VERSION "MUR_Telemetry_CAN_v1.1"

NS_ :

BS_:

BU_: DASH PDU SBG TELEMETRY ECU

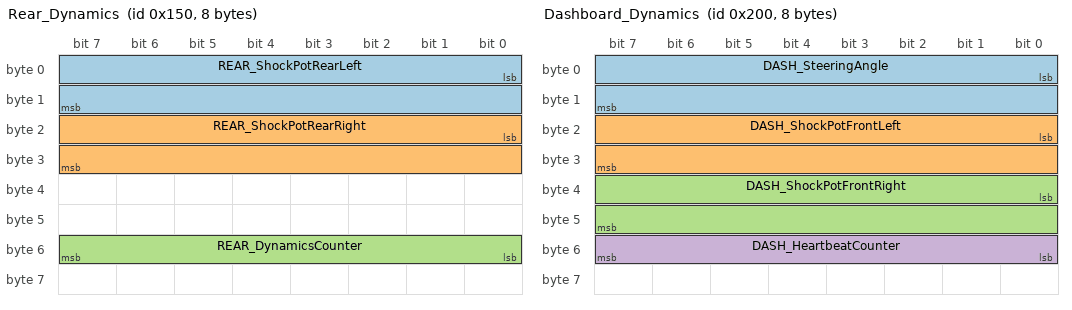
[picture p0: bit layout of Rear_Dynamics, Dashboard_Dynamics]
BO_ 336 Rear_Dynamics: 8 ECU
 SG_ REAR_ShockPotRearLeft : 0|16@1+ (0.1,0) [0|500] "mm" TELEMETRY
 SG_ REAR_ShockPotRearRight : 16|16@1+ (0.1,0) [0|500] "mm" TELEMETRY
 SG_ REAR_DynamicsCounter : 48|8@1+ (1,0) [0|255] "" TELEMETRY

BO_ 512 Dashboard_Dynamics: 8 DASH
 SG_ DASH_SteeringAngle : 0|16@1- (0.1,0) [-1800|1800] "deg" TELEMETRY
 SG_ DASH_ShockPotFrontLeft : 16|16@1+ (0.1,0) [0|500] "mm" TELEMETRY
 SG_ DASH_ShockPotFrontRight : 32|16@1+ (0.1,0) [0|500] "mm" TELEMETRY
 SG_ DASH_HeartbeatCounter : 48|8@1+ (1,0) [0|255] "" TELEMETRY

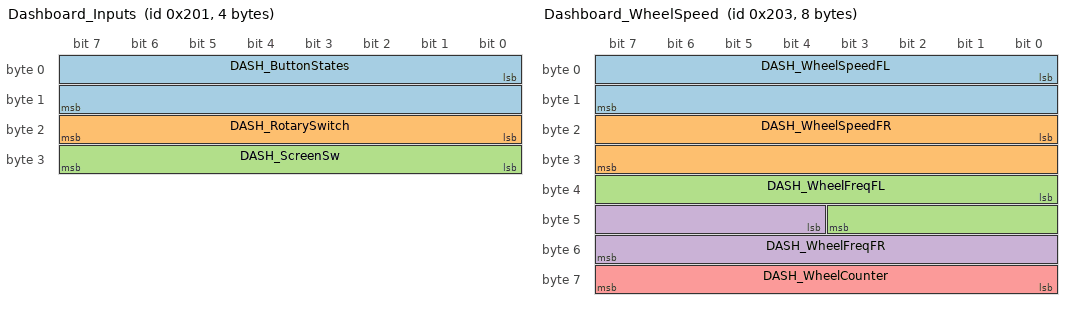
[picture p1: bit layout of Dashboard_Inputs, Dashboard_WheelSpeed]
BO_ 513 Dashboard_Inputs: 4 DASH
 SG_ DASH_ButtonStates : 0|16@1+ (1,0) [0|65535] "" TELEMETRY
 SG_ DASH_RotarySwitch : 16|8@1+ (1,0) [0|15] "" TELEMETRY
 SG_ DASH_ScreenSw : 24|8@1+ (1,0) [0|255] "" TELEMETRY,ECU

BO_ 514 Dashboard_Environment: 4 DASH
 SG_ DASH_WindSpeed : 0|16@1+ (0.1,0) [0|6553.5] "m/s" TELEMETRY

BO_ 515 Dashboard_WheelSpeed: 8 DASH
 SG_ DASH_WheelSpeedFL : 0|16@1+ (0.1,0) [0|6553.4] "rpm" TELEMETRY
 SG_ DASH_WheelSpeedFR : 16|16@1+ (0.1,0) [0|6553.4] "rpm" TELEMETRY
 SG_ DASH_WheelFreqFL : 32|12@1+ (1,0) [0|4095] "Hz" TELEMETRY
 SG_ DASH_WheelFreqFR : 44|12@1+ (1,0) [0|4095] "Hz" TELEMETRY
 SG_ DASH_WheelCounter : 56|8@1+ (1,0) [0|255] "" TELEMETRY

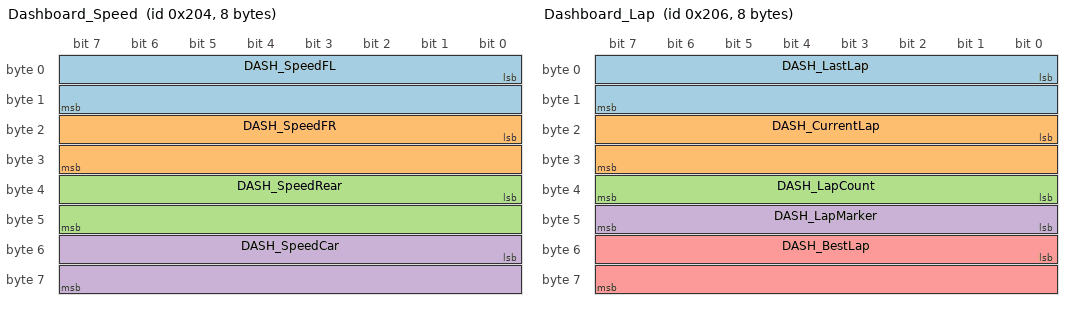
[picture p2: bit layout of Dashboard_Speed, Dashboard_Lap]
BO_ 516 Dashboard_Speed: 8 DASH
 SG_ DASH_SpeedFL : 0|16@1+ (0.1,0) [0|6553.4] "km/h" TELEMETRY
 SG_ DASH_SpeedFR : 16|16@1+ (0.1,0) [0|6553.4] "km/h" TELEMETRY
 SG_ DASH_SpeedRear : 32|16@1+ (0.1,0) [0|6553.4] "km/h" TELEMETRY
 SG_ DASH_SpeedCar : 48|16@1+ (0.1,0) [0|6553.4] "km/h" TELEMETRY

BO_ 518 Dashboard_Lap: 8 DASH
 SG_ DASH_LastLap : 0|16@1+ (0.01,0) [0|655.34] "s" TELEMETRY
 SG_ DASH_CurrentLap : 16|16@1+ (0.01,0) [0|655.34] "s" TELEMETRY
 SG_ DASH_LapCount : 32|8@1+ (1,0) [0|255] "" TELEMETRY
 SG_ DASH_LapMarker : 40|8@1+ (1,0) [0|1] "" TELEMETRY
 SG_ DASH_BestLap : 48|16@1+ (0.01,0) [0|655.34] "s" TELEMETRY

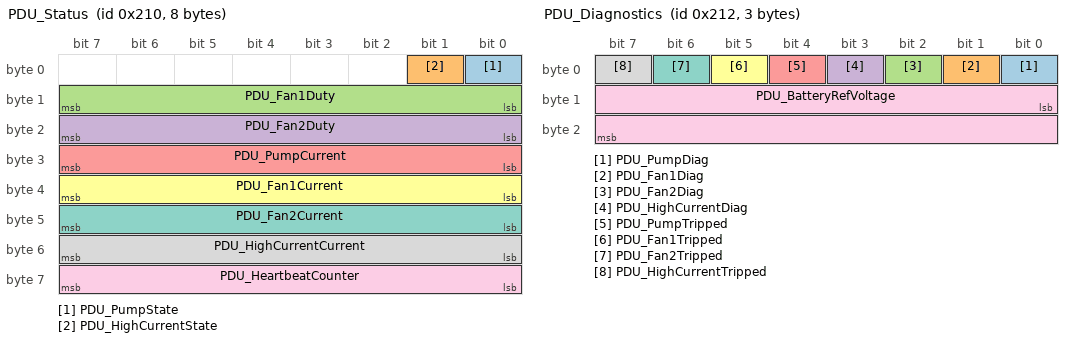
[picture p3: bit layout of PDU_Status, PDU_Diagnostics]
BO_ 528 PDU_Status: 8 PDU
 SG_ PDU_PumpState : 0|1@1+ (1,0) [0|1] "" TELEMETRY,ECU
 SG_ PDU_HighCurrentState : 1|1@1+ (1,0) [0|1] "" TELEMETRY,ECU
 SG_ PDU_Fan1Duty : 8|8@1+ (1,0) [0|100] "%" TELEMETRY,ECU
 SG_ PDU_Fan2Duty : 16|8@1+ (1,0) [0|100] "%" TELEMETRY,ECU
 SG_ PDU_PumpCurrent : 24|8@1+ (0.1,0) [0|25.5] "A" TELEMETRY,ECU
 SG_ PDU_Fan1Current : 32|8@1+ (0.1,0) [0|25.5] "A" TELEMETRY,ECU
 SG_ PDU_Fan2Current : 40|8@1+ (0.1,0) [0|25.5] "A" TELEMETRY,ECU
 SG_ PDU_HighCurrentCurrent : 48|8@1+ (0.1,0) [0|25.5] "A" TELEMETRY,ECU
 SG_ PDU_HeartbeatCounter : 56|8@1+ (1,0) [0|255] "" TELEMETRY

BO_ 530 PDU_Diagnostics: 3 PDU
 SG_ PDU_PumpDiag : 0|1@1+ (1,0) [0|1] "" TELEMETRY,ECU
 SG_ PDU_Fan1Diag : 1|1@1+ (1,0) [0|1] "" TELEMETRY,ECU
 SG_ PDU_Fan2Diag : 2|1@1+ (1,0) [0|1] "" TELEMETRY,ECU
 SG_ PDU_HighCurrentDiag : 3|1@1+ (1,0) [0|1] "" TELEMETRY,ECU
 SG_ PDU_PumpTripped : 4|1@1+ (1,0) [0|1] "" TELEMETRY,ECU
 SG_ PDU_Fan1Tripped : 5|1@1+ (1,0) [0|1] "" TELEMETRY,ECU
 SG_ PDU_Fan2Tripped : 6|1@1+ (1,0) [0|1] "" TELEMETRY,ECU
 SG_ PDU_HighCurrentTripped : 7|1@1+ (1,0) [0|1] "" TELEMETRY,ECU
 SG_ PDU_BatteryRefVoltage : 8|16@1+ (0.01,0) [0|655.35] "V" TELEMETRY,ECU

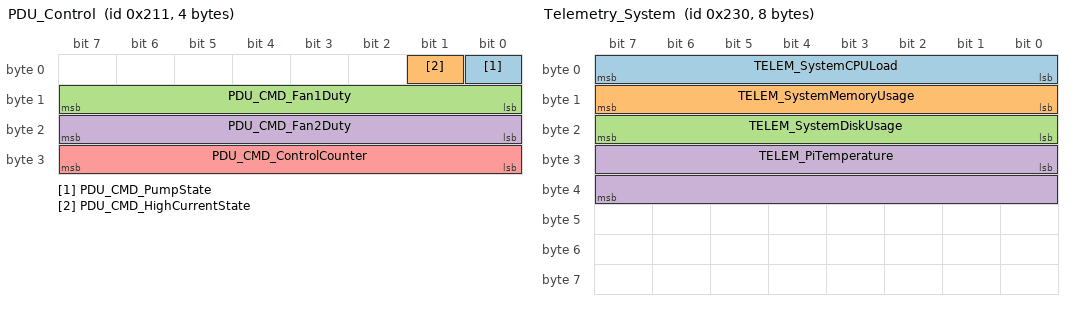
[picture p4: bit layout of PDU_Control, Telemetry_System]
BO_ 529 PDU_Control: 4 ECU
 SG_ PDU_CMD_PumpState : 0|1@1+ (1,0) [0|1] "" PDU,TELEMETRY
 SG_ PDU_CMD_HighCurrentState : 1|1@1+ (1,0) [0|1] "" PDU,TELEMETRY
 SG_ PDU_CMD_Fan1Duty : 8|8@1+ (1,0) [0|100] "%" PDU,TELEMETRY
 SG_ PDU_CMD_Fan2Duty : 16|8@1+ (1,0) [0|100] "%" PDU,TELEMETRY
 SG_ PDU_CMD_ControlCounter : 24|8@1+ (1,0) [0|255] "" PDU,TELEMETRY

BO_ 560 Telemetry_System: 8 TELEMETRY
 SG_ TELEM_SystemCPULoad : 0|8@1+ (1,0) [0|100] "%" DASH
 SG_ TELEM_SystemMemoryUsage : 8|8@1+ (1,0) [0|100] "%" DASH
 SG_ TELEM_SystemDiskUsage : 16|8@1+ (1,0) [0|100] "%" DASH
 SG_ TELEM_PiTemperature : 24|16@1- (0.1,0) [-3276.8|3276.7] "degC" DASH

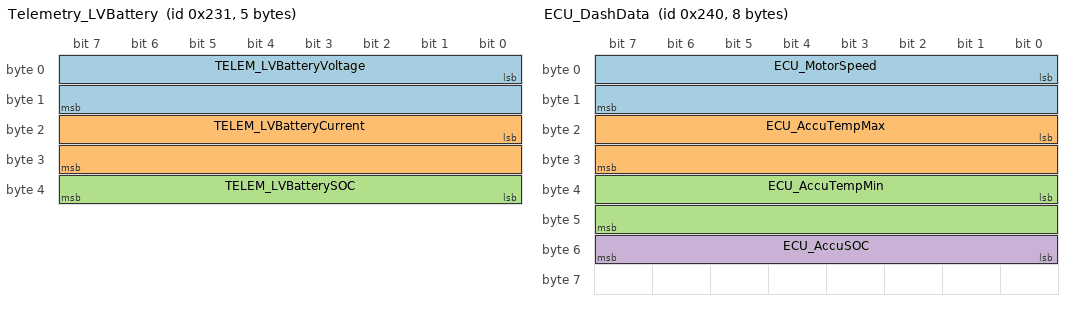
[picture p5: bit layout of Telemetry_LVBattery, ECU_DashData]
BO_ 561 Telemetry_LVBattery: 5 TELEMETRY
 SG_ TELEM_LVBatteryVoltage : 0|16@1+ (0.01,0) [0|655.35] "V" DASH,ECU
 SG_ TELEM_LVBatteryCurrent : 16|16@1- (0.1,0) [-3276.8|3276.7] "A" DASH,ECU
 SG_ TELEM_LVBatterySOC : 32|8@1+ (1,0) [0|100] "%" DASH,ECU

BO_ 576 ECU_DashData: 8 ECU
 SG_ ECU_MotorSpeed : 0|16@1+ (1,0) [0|10000] "rpm" DASH,TELEMETRY
 SG_ ECU_AccuTempMax : 16|16@1- (0.1,0) [-3276.8|3276.7] "degC" DASH,TELEMETRY
 SG_ ECU_AccuTempMin : 32|16@1- (0.1,0) [-3276.8|3276.7] "degC" DASH,TELEMETRY
 SG_ ECU_AccuSOC : 48|8@1+ (1,0) [0|100] "%" DASH,TELEMETRY

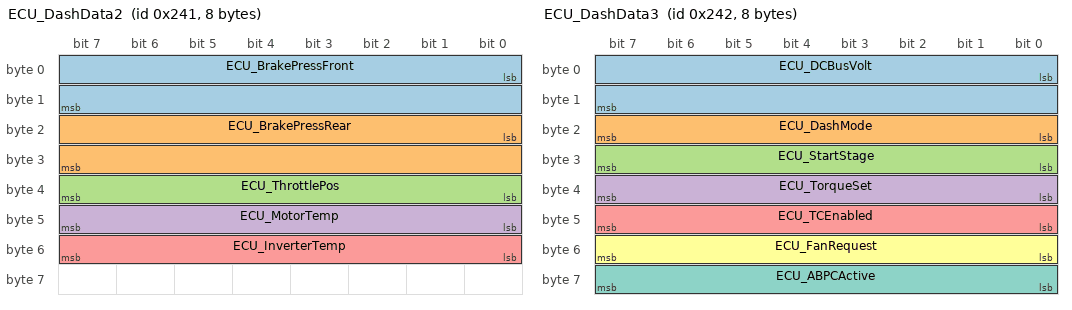
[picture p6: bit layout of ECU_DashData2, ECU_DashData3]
BO_ 577 ECU_DashData2: 8 ECU
 SG_ ECU_BrakePressFront : 0|16@1+ (0.1,0) [0|2000] "psi" DASH,TELEMETRY
 SG_ ECU_BrakePressRear : 16|16@1+ (0.1,0) [0|2000] "psi" DASH,TELEMETRY
 SG_ ECU_ThrottlePos : 32|8@1+ (1,0) [0|100] "%" DASH,TELEMETRY
 SG_ ECU_MotorTemp : 40|8@1+ (1,-40) [-40|214] "degC" DASH,TELEMETRY
 SG_ ECU_InverterTemp : 48|8@1+ (1,-40) [-40|214] "degC" DASH,TELEMETRY

BO_ 578 ECU_DashData3: 8 ECU
 SG_ ECU_DCBusVolt : 0|16@1+ (0.1,0) [0|500] "V" DASH,TELEMETRY
 SG_ ECU_DashMode : 16|8@1+ (1,0) [0|5] "" DASH,TELEMETRY
 SG_ ECU_StartStage : 24|8@1+ (1,0) [0|4] "" DASH,TELEMETRY
 SG_ ECU_TorqueSet : 32|8@1+ (1,0) [0|254] "Nm" DASH,TELEMETRY
 SG_ ECU_TCEnabled : 40|8@1+ (1,0) [0|1] "" DASH,TELEMETRY
 SG_ ECU_FanRequest : 48|8@1+ (1,0) [0|1] "" DASH,TELEMETRY
 SG_ ECU_ABPCActive : 56|8@1+ (1,0) [0|1] "" DASH,TELEMETRY

BO_ 579 ECU_DashSOC: 2 ECU
 SG_ ECU_AccuSOCMin : 0|16@1+ (0.1,0) [0|100] "%" DASH,TELEMETRY

BO_ 128 MUR_Fault: 8 Vector__XXX
 SG_ FAULT_Node M : 0|8@1+ (1,0) [0|255] "" TELEMETRY
 SG_ FAULT_Bitmask_Pedalbox m1 : 8|32@1+ (1,0) [0|4294967295] "" TELEMETRY
 SG_ FAULT_Bitmask_Dash m2 : 8|32@1+ (1,0) [0|4294967295] "" TELEMETRY
 SG_ FAULT_Bitmask_Rear m3 : 8|32@1+ (1,0) [0|4294967295] "" TELEMETRY
 SG_ FAULT_Bitmask_TTCS m4 : 8|32@1+ (1,0) [0|4294967295] "" TELEMETRY
 SG_ FAULT_Bitmask_Charger m5 : 8|32@1+ (1,0) [0|4294967295] "" TELEMETRY
 SG_ FAULT_Counter : 56|8@1+ (1,0) [0|255] "" TELEMETRY

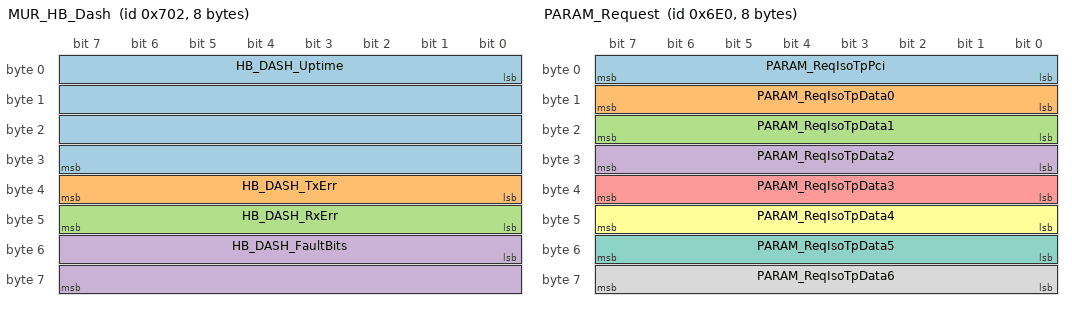
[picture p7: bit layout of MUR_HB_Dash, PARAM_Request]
BO_ 1794 MUR_HB_Dash: 8 DASH
 SG_ HB_DASH_Uptime : 0|32@1+ (1,0) [0|4294967295] "s" TELEMETRY
 SG_ HB_DASH_TxErr : 32|8@1+ (1,0) [0|255] "" TELEMETRY
 SG_ HB_DASH_RxErr : 40|8@1+ (1,0) [0|255] "" TELEMETRY
 SG_ HB_DASH_FaultBits : 48|16@1+ (1,0) [0|65535] "" TELEMETRY

BO_ 1760 PARAM_Request: 8 Vector__XXX
 SG_ PARAM_ReqIsoTpPci : 0|8@1+ (1,0) [0|255] "" Vector__XXX
 SG_ PARAM_ReqIsoTpData0 : 8|8@1+ (1,0) [0|255] "" Vector__XXX
 SG_ PARAM_ReqIsoTpData1 : 16|8@1+ (1,0) [0|255] "" Vector__XXX
 SG_ PARAM_ReqIsoTpData2 : 24|8@1+ (1,0) [0|255] "" Vector__XXX
 SG_ PARAM_ReqIsoTpData3 : 32|8@1+ (1,0) [0|255] "" Vector__XXX
 SG_ PARAM_ReqIsoTpData4 : 40|8@1+ (1,0) [0|255] "" Vector__XXX
 SG_ PARAM_ReqIsoTpData5 : 48|8@1+ (1,0) [0|255] "" Vector__XXX
 SG_ PARAM_ReqIsoTpData6 : 56|8@1+ (1,0) [0|255] "" Vector__XXX

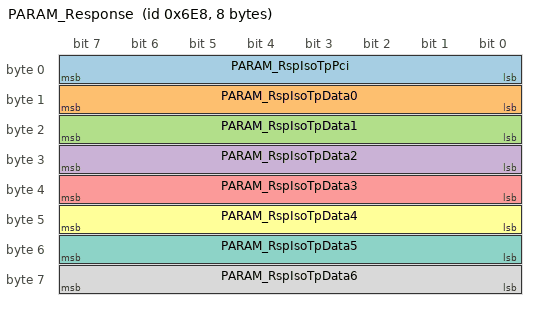
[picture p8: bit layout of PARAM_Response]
BO_ 1768 PARAM_Response: 8 Vector__XXX
 SG_ PARAM_RspIsoTpPci : 0|8@1+ (1,0) [0|255] "" Vector__XXX
 SG_ PARAM_RspIsoTpData0 : 8|8@1+ (1,0) [0|255] "" Vector__XXX
 SG_ PARAM_RspIsoTpData1 : 16|8@1+ (1,0) [0|255] "" Vector__XXX
 SG_ PARAM_RspIsoTpData2 : 24|8@1+ (1,0) [0|255] "" Vector__XXX
 SG_ PARAM_RspIsoTpData3 : 32|8@1+ (1,0) [0|255] "" Vector__XXX
 SG_ PARAM_RspIsoTpData4 : 40|8@1+ (1,0) [0|255] "" Vector__XXX
 SG_ PARAM_RspIsoTpData5 : 48|8@1+ (1,0) [0|255] "" Vector__XXX
 SG_ PARAM_RspIsoTpData6 : 56|8@1+ (1,0) [0|255] "" Vector__XXX

CM_ BU_ DASH "Dashboard Sensor Node - steering, shock pots, driver buttons, front wheel speeds, wind speed";
CM_ BU_ PDU "Power Distribution Unit - 4 switched high-side outputs (Pump, Fan1, Fan2, HighCurrent) each with current sense + hardware diagnostic feedback, per the PDM_M26 hardware bring-up. Design brief only defined PDU_Status (receive-only feedback, no command messages); PDU_Control and PDU_Diagnostics are MUR additions (see their CM_ comments).";
CM_ BU_ SBG "2x SBG Ellipse-D GNSS/INS units (front + rear). CAN ID block 0x220-0x22F reserved for SBG traffic: front 0x220-0x227, rear 0x228-0x22F. Frames are defined in vendor/SBG_Ellipse.dbc (derived from SBG's official sbgCan.dbc, IDs remapped in sbgCenter), not here - load that file alongside this one.";
CM_ BU_ TELEMETRY "Telemetry Unit (Raspberry Pi) - silently captures all Telemetry CAN traffic, also broadcasts system health + LV battery data";
CM_ BU_ ECU "Engine/Electronic Control Unit - dual-homed node, also on Control CAN (see control_can DBC). Previously listed as a receiver of PDU_Status and Telemetry_LVBattery without being declared here. HARDWARE NOTE: requires a second CAN transceiver on the ECU - confirm before finalising.";
CM_ BO_ 336 "ECU rear shockpots, 100 Hz on Telemetry CAN. Same wire layout as the legacy Control CAN Rear_Dynamics used by sn_demo. AIN1/PB1 = left, AIN0/PA6 = right. Firmware defaults to pin-mV bench mode until per-corner calibration exists: raw fields contain ADC pin millivolts, so divide DBC-decoded travel by 0.1 to recover mV. 0xFFFF = invalid; calibrated mode uses the declared 0.1 mm/count scale.";
CM_ BO_ 512 "Dashboard steering/suspension + heartbeat. Transmit rate 100 Hz (FAST).";
CM_ SG_ 512 DASH_SteeringAngle "Signed to allow left/right steering deflection.";
CM_ BO_ 513 "Dashboard driver button states + rotary mode switch. Transmit rate 20 Hz.";
CM_ SG_ 513 DASH_ButtonStates "Bit-per-button: bit i = the dashboard's din-gpios[i], debounced, 1 = pressed. Per the team's pinout (2026-11-14): bit 2 = ready-to-drive (DIN[2], PC0), bit 4 = torque down (DIN[4], PA3), bit 5 = torque up (DIN[5], PA4), bit 6 = fans on/off (DIN[6], PA5), bit 7 = drive mode (DIN[7], PA7). Bits 3 and 8 are the wheel-speed encoder DINs, always 0 here. main_compute's MC_DASH_BTN_* constants must match.";
CM_ SG_ 513 DASH_RotarySwitch "Rotary switch position index (0-15). ASSUMPTION - confirm number of switch positions.";
CM_ SG_ 513 DASH_ScreenSw "MUR ADDITION (PROVISIONAL): the screen's CAN switches as last received on Dash CAN (Screen_Switches there), relayed so the ECU can act on them: bits 0-6 = CAN switches 1-7 (bit n-1 = switch n): 1 = torque down, 2 = torque up, 3 = traction control; 4 is unused (it set the GPS lap marker until 2026-11-19; laps are now marked with the RTD button, see Dashboard_Lap). Bit 7 = 1 while the screen is being heard (a Screen_Switches frame within the last 500 ms); while it is 0 the whole byte is 0 and means nothing. The screen's switches are toggles, so a CHANGE of bits 0-6 is one press, in either direction - but only between two samples with bit 7 set: the ECU takes the first sample after the screen (re)appears as its new baseline, since a rebooted screen comes back with its switches reset.";
CM_ BO_ 514 "Dashboard wind speed sensor. Transmit rate 10 Hz (MEDIUM).";
CM_ BO_ 515 "MUR ADDITION (PROVISIONAL): front wheel speeds from the two encoder DINs on the dashboard node (DIN[3] PC13 = FL, DIN[8] PC5 = FR), measured by EXTI edge timing (firmware/lib/dash/dash_wheel). Transmit rate 100 Hz (FAST).";
CM_ SG_ 515 DASH_WheelSpeedFL "Wheel rpm = pulse frequency x 60 / pulses-per-rev. 0xFFFF (6553.5) = invalid: encoder pulses-per-rev not calibrated yet (TODO(calib)) - read DASH_WheelFreqFL instead. 0 after ~0.5 s with no pulse.";
CM_ SG_ 515 DASH_WheelSpeedFR "See DASH_WheelSpeedFL.";
CM_ SG_ 515 DASH_WheelFreqFL "Raw encoder pulse frequency, independent of any calibration - the bench/sanity view. Saturates at 4095 (= at least 4095 Hz).";
CM_ SG_ 515 DASH_WheelFreqFR "See DASH_WheelFreqFL.";
CM_ SG_ 515 DASH_WheelCounter "Increments every frame; a frozen counter means a stalled node.";
CM_ BO_ 528 "MUR ADDITION (PROVISIONAL - pending telemetry team sign-off): supersedes the original 2-bit pump/fan on-off design-brief layout with the real PDM_M26 hardware's 4-channel shape (Pump/Fan1/Fan2/HighCurrent) - this was the 'byte 2 reserved for future PDU_FanSpeed' the original comment anticipated, now split into per-fan duty since there are two independently-driven fans. PDU_Fan1Duty/PDU_Fan2Duty are 0-100% PWM duty (0 = off); Pump/HighCurrent are simple on/off high-side switches with no PWM hardware. Currents are the per-channel sense readings (0.1 A/LSB) used for the firmware's own overcurrent protection, republished here for telemetry. Diagnostic pin state and latched trip flags moved to PDU_Diagnostics (0x212) to keep this message's transmit rate (10 Hz) fast without carrying slow-changing fault bits. Transmit rate unchanged at 10 Hz (SLOW).";
CM_ BO_ 530 "MUR ADDITION (PROVISIONAL - pending telemetry team sign-off): PDU per-channel hardware diagnostic pin state (fault while driven) and latched software overcurrent-trip flags, split out of PDU_Status since these change far less often. Also carries PDU_BatteryRefVoltage (PDM_M26's PA0 sense channel) for LV rail monitoring. Transmit rate 2 Hz (SLOW).";
CM_ BO_ 529 "MUR ADDITION (PROVISIONAL - pending telemetry team sign-off): ECU-to-PDU command, added because PDU_Status (0x210) is receive-only feedback with no corresponding command message defined anywhere in this bus's design brief, yet the ECU/VCU role genuinely needs to drive pump/fan/high-current state (cooling-loop control tied to Car.Data.State and DrivingState in the ported control logic). Extended alongside PDU_Status's 2026 hardware-accurate redesign: PDU_CMD_Fan1Duty/PDU_CMD_Fan2Duty (0-100% PWM) replace the old single fan on/off bit, PDU_CMD_HighCurrentState added. ControlCounter kept at the end of the frame so a frozen command stream is detectable the same way other MUR-added messages already are (see MUR_HB_* / Rear_* counter convention) - PDM firmware fails all four channels to OFF/0% if this counter stops advancing. Transmit rate: on-change plus a slow cyclic backstop, TBD alongside the rest of this file's provisional messages.";
CM_ BO_ 560 "Telemetry Pi system health (CPU/mem/disk/temp), broadcast for dashboard display. Transmit rate 5 Hz.";
CM_ BO_ 561 "Telemetry Pi: the LV battery with the lower state of charge. The Pi reads both Allion AL1220-BT batteries over Bluetooth (bms_telemetry) and sends this frame for whichever fresh battery reports the lower SoC; voltage and current are that same battery's. A battery is fresh if it reported in the last 10 s. With no fresh battery the frame is still sent, with every signal at its invalid value. No frame at all means the Pi or its bridge is down. Transmit rate 2 Hz (SLOW).";
CM_ SG_ 561 TELEM_LVBatteryVoltage "LV battery terminal voltage, from the battery's own BMS. Raw 0xFFFF = invalid (no fresh battery). Battery reports mV: assumed from its readings, not yet checked against a meter.";
CM_ SG_ 561 TELEM_LVBatteryCurrent "LV battery current, from the battery's own BMS; positive = discharging, negative = charging (the battery's own sign). Raw 0x7FFF = invalid (no fresh battery). Battery reports mA: assumed, not yet checked against a clamp meter.";
CM_ SG_ 561 TELEM_LVBatterySOC "State of charge of the lower of the LV batteries, whole percent, rounded down from the battery BMS's 0.01 % value. Raw 0xFF = invalid (no fresh battery). Only as good as the battery's own SoC estimate.";
CM_ BO_ 128 "MUR ADDITION (PROVISIONAL - pending telemetry team sign-off): latched fault broadcast, any MUR sensor node transmits on fault raise (EVENT). FAULT_Node identifies the sender (1=Pedalbox 2=Dashboard 3=Rear 4=TTCS). Same message exists on Control CAN for nodes homed there.";
CM_ SG_ 128 FAULT_Node "Sending node, and the multiplexor: each node's fault mask has its own FAULT_Bitmask_<node> signal, because the bit numbers mean different faults on each node.";
CM_ SG_ 128 FAULT_Bitmask_Pedalbox "The Pedalbox's latched fault mask, sent when FAULT_Node is the Pedalbox. Same bits as PEDAL_BSEStatus and HB_PEDAL_FaultBits (firmware/lib/pedal/include/pedal_faults.h in mur-embedded). Bits 2 to 6 are reserved there and not raised yet.
bit 0: APPS implausible; Accelerator pedal sensors disagree; warning
bit 1: Pedal cal invalid; Pedalbox calibration invalid; warning
bit 2: BSE active; Brake system encoder active; warning
bit 3: BSPD trip; BSPD fault, shutdown circuit opened; shutdown
bit 4: APPS A out of range; Accelerator pedal sensor A outside its plausible range; warning
bit 5: APPS B out of range; Accelerator pedal sensor B outside its plausible range; warning
bit 6: Brake out of range; Brake pressure sensor outside its plausible range; warning";
CM_ SG_ 128 FAULT_Bitmask_Dash "The dashboard's latched fault mask, sent when FAULT_Node is the dashboard. Only bit 0 is used (firmware/apps/dashboard in mur-embedded); the real fault map is still TBD.
bit 0: Analog dead; Dashboard ADC failed to start; warning";
CM_ SG_ 128 FAULT_Bitmask_Rear "The rear node's latched fault mask, sent when FAULT_Node is the rear node. There is no rear node firmware yet; bit 0 is the bench convention firmware/apps/sn_demo in mur-embedded uses.
bit 0: Analog dead; Rear node ADC failed to start; warning";
CM_ SG_ 128 FAULT_Bitmask_TTCS "The car TTCS's full latched fault mask, sent when FAULT_Node is the TTCS (firmware/lib/ttcs/include/ttcs_faults.h in mur-embedded). HB_TTCS_FaultBits carries only the low 16 bits; bits 16 and 17 reach only this signal. Bits 0 to 2 mirror the MSS fault lines live and the MSS itself opens the shutdown circuit for them. The other shutdown bits are TTCS_SDC_TRIP_MASK, still provisional pending safety-team sign-off. The car app never raises the charger bits 18 to 21.
bit 0: IMD trip; IMD fault, shutdown circuit opened; shutdown
bit 1: PDOC trip; PDOC fault, shutdown circuit opened; shutdown
bit 2: BMS trip; BMS fault, shutdown circuit opened; shutdown
bit 3: HV overcurrent; HV overcurrent measured by the TTCS; shutdown
bit 4: ENNOID comms lost; ENNOID BMS status stream stale; shutdown
bit 5: ECU comms lost; ECU_Status stream stale; shutdown
bit 6: AIR implausible; AIR feedback disagrees with the expected state; warning
bit 7: IMD no signal; No PWM edges from the IMD; warning
bit 8: Cell overvoltage; Highest cell voltage over its limit; shutdown
bit 9: Cell undervoltage; Lowest cell voltage under its limit; shutdown
bit 10: Pack overvoltage; Pack voltage over its limit; shutdown
bit 11: Pack undervoltage; Pack voltage under its limit; shutdown
bit 12: Battery overtemp; Battery high temperature over its limit; shutdown
bit 13: Current while blocked; Current flowing while the ENNOID BMS prohibits it; shutdown
bit 14: Current mismatch; TTCS and ENNOID current readings disagree; shutdown
bit 15: Battery data bad; Battery data implausible or calibration not configured; shutdown
bit 16: Cell imbalance; Weak or imbalanced cell, derate and investigate; warning
bit 17: Current over limit; Current far above the computed discharge or charge limit for a sustained window; shutdown";
CM_ SG_ 128 FAULT_Bitmask_Charger "The charge-cart TTCS board's latched fault mask, sent when FAULT_Node is the charger (firmware/apps/charger in mur-embedded, cart bus only). Same bit numbers as the car TTCS; shutdown marks TTCS_CART_SDC_TRIP_MASK, still provisional pending safety-team sign-off. The cart has no ECU, so bit 5 is never raised there.
bit 0: IMD trip; IMD fault, shutdown circuit opened; shutdown
bit 1: PDOC trip; PDOC fault line asserted, not a cart trip; warning
bit 2: BMS trip; BMS fault, shutdown circuit opened; shutdown
bit 3: HV overcurrent; HV overcurrent measured by the TTCS; warning
bit 4: ENNOID comms lost; ENNOID BMS status stream stale; shutdown
bit 6: AIR implausible; AIR feedback disagrees with the expected state; warning
bit 7: IMD no signal; No PWM edges from the IMD; warning
bit 8: Cell overvoltage; Highest cell voltage over its limit; shutdown
bit 9: Cell undervoltage; Lowest cell voltage under its limit; shutdown
bit 10: Pack overvoltage; Pack voltage over its limit; shutdown
bit 11: Pack undervoltage; Pack voltage under its limit; shutdown
bit 12: Battery overtemp; Battery high temperature over its limit; shutdown
bit 13: Current while blocked; Current flowing while the ENNOID BMS prohibits it; shutdown
bit 14: Current mismatch; TTCS and ENNOID current readings disagree; warning
bit 15: Battery data bad; Battery data implausible or calibration not configured; shutdown
bit 16: Cell imbalance; Weak or imbalanced cell, derate and investigate; warning
bit 17: Current over limit; Current far above the computed discharge or charge limit for a sustained window; shutdown
bit 18: Charger comms lost; Charger status stale while charging; shutdown
bit 19: Charger fault; Charger reports its own fault; shutdown
bit 20: Charger voltage mismatch; Charger output voltage disagrees with the ENNOID pack voltage; shutdown
bit 21: Charger overcurrent; Charger output current above its command plus tolerance; shutdown";
CM_ BO_ 576 "MUR ADDITION (PROVISIONAL): driver-display data from the ECU, which sits on both Tractive and Telemetry CAN and can see what the dashboard cannot. Transmit rate 10 Hz (the ECU's best-effort thread). 8 bytes from day one; byte 7 is still reserved: add new display signals there, byte-aligned and 8 or 16 bits wide so the MFD28's DSS import reads them cleanly, and never move, resize or rescale an existing one. The dashboard forwards this frame to Dash CAN byte-for-byte, so it must stay identical in mur_dashboard_can.dbc (scripts/validate.py checks); adding a signal then needs no dashboard firmware change.";
CM_ SG_ 576 ECU_MotorSpeed "Motor speed magnitude in rpm, from the inverter's INV_MotorPosition on Tractive CAN, clipped to 0-10000 by the ECU; no direction. 0xFFFF = invalid: the ECU has not heard the inverter yet, or has lost it (comms timeout).";
CM_ SG_ 576 ECU_AccuTempMax "Canonical car accumulator maximum, converted by ECU using voltage recovery and Table 5. Prefer complete fresh sweeps; if no sweep frames are fresh, use a fresh mapped summary maximum (1 degC input resolution). Partial or invalid live sweeps prevent fallback. 0x7FFF is invalid. Identical ECU_DashData bytes reach TTCS on Control CAN and screen on Telemetry/Dash CAN.";
CM_ SG_ 576 ECU_AccuTempMin "Corrected minimum from complete fresh sensor sweeps. 0x7FFF is invalid, including during summary-maximum fallback; summary supplies no minimum.";
CM_ SG_ 576 ECU_AccuSOC "Accumulator SOC in whole percent. ECU firmware with ECU_DashSOC derives this from TTCS_ModelSOCMin; older firmware uses ENNOID summary SOC. 0xFF = unavailable.";
CM_ BO_ 579 "Driver display SOC at 10 Hz. ECU publishes on Telemetry CAN; dashboard forwards the same bytes to Dash CAN.";
CM_ SG_ 579 ECU_AccuSOCMin "Lowest TTCS model group SOC at 0.1 percent per count. Raw 0xFFFF (6553.5 percent) means TTCS SOC is invalid or stale. Display only.";
CM_ BO_ 516 "MUR ADDITION (PROVISIONAL): wheel speeds in km/h for the driver's screen, computed on the dashboard node (firmware/lib/dash/dash_speed) and sent with identical bytes on Telemetry and Dash CAN (scripts/validate.py FORWARDED keeps the two definitions the same). Transmit rate 20 Hz. Same equations as mur-embedded's tools/bench/mur_can.py: 0.0766 km/h per wheel rpm (a 16 in tyre, assumed from the factor, not measured on the car).";
CM_ SG_ 516 DASH_SpeedFL "Front left wheel km/h = DASH_WheelSpeedFL x 0.0766. 0xFFFF (6553.5) = invalid whenever DASH_WheelSpeedFL is.";
CM_ SG_ 516 DASH_SpeedFR "Front right wheel km/h; see DASH_SpeedFL.";
CM_ BO_ 518 "MUR ADDITION (PROVISIONAL): lap timing for the driver's screen, computed on the dashboard node (firmware/lib/dash/dash_lap) from presses of the driver's ready-to-drive (RTD) button, and sent with identical bytes on Telemetry and Dash CAN (scripts/validate.py FORWARDED). Transmit rate 10 Hz. Bytes 6-7 carry the best lap. Manual timing with no GPS (maintainer direction 2026-11-19): while the car is ready to drive (ECU_DashData3 ECU_StartStage 4, heard within 500 ms), each press of the RTD button (a rising edge of Dashboard_Inputs DASH_ButtonStates bit 2) is a lap marker. The first press starts the lap clock; each later press ends the current lap and starts the next, unless it comes less than 2 s after the lap started, which is ignored so a double press cannot record a near-zero lap. Presses while the car is not ready to drive are ignored, including the press that arms ready-to-drive. Entering ready-to-drive clears the lap times and count. Every press goes through the same 30 ms debounce, so a lap time is as good as the driver's timing of the press. Bench-unverified. Lives in RAM: a dashboard reset also clears it.";
CM_ SG_ 518 DASH_LastLap "Time of the last completed lap. 0xFFFF (655.35) = none yet: no lap completed since the car last entered ready-to-drive (or since the dashboard started). A lap longer than 655.34 s reads 655.34.";
CM_ SG_ 518 DASH_CurrentLap "Time since the current lap started. 0xFFFF (655.35) = lap timing not started: no RTD-button lap press since the car last entered ready-to-drive. Saturates at 655.34.";
CM_ SG_ 518 DASH_LapCount "Laps completed since the car last entered ready-to-drive; wraps at 255.";
CM_ SG_ 518 DASH_BestLap "Fastest lap completed since the car last entered ready-to-drive. 0xFFFF (655.35) = none yet.";
CM_ SG_ 518 DASH_LapMarker "1 = lap timing is running: the RTD button has been pressed as a lap marker since the car last entered ready-to-drive. 0 = not started. Until 2026-11-19 this meant a GPS start/finish marker was set; the GPS lap timer has been removed.";
CM_ SG_ 516 DASH_SpeedRear "Rear wheel km/h from motor speed, there being no rear wheel sensor: ECU_MotorSpeed / 4.777 (the final drive ratio as given by the team 2026-11-01) x 0.0766. The diff makes it the average of the two rear wheels, so it reads a little off from either one in a corner. 0xFFFF (6553.5) = invalid: ECU_MotorSpeed is invalid, or the dashboard has had no ECU_DashData for 500 ms.";
CM_ SG_ 516 DASH_SpeedCar "MUR ADDITION (PROVISIONAL): one car speed for the screen's speed readouts (the lap-timing and autocross pages): the mean of DASH_SpeedFL and DASH_SpeedFR, or whichever one is valid. The fronts are undriven, so wheelspin does not inflate it, unlike DASH_SpeedRear. 0xFFFF (6553.5) = invalid: neither front speed is valid.";
CM_ BO_ 577 "MUR ADDITION (PROVISIONAL): more driver-display data from the ECU, ECU_DashData being full: brake pressures and throttle from the pedalbox's Pedal_Status, motor and inverter temperatures from the inverter, all on Tractive CAN. Transmit rate 10 Hz (the ECU's best-effort thread). The dashboard forwards it to Dash CAN byte-for-byte, so it must stay identical in mur_dashboard_can.dbc (scripts/validate.py FORWARDED). Byte 7 reserved: add display signals there, byte-aligned and 8 or 16 bits wide, never moving, resizing or rescaling an existing one.";
CM_ SG_ 577 ECU_BrakePressFront "PEDAL_BrakePressure1 (front circuit) as the ECU last received it. 0xFFFF (6553.5) = invalid: the ECU has not heard Pedal_Status yet, or it has timed out or frozen (the ECU's pedal comm_err).";
CM_ SG_ 577 ECU_BrakePressRear "PEDAL_BrakePressure2 (rear circuit); see ECU_BrakePressFront.";
CM_ SG_ 577 ECU_ThrottlePos "Accelerator pedal: the mean of PEDAL_Position1 and PEDAL_Position2, rounded to whole %. Shown even when the two disagree; APPS plausibility is the ECU's fault logic, not the screen's. 0xFF = invalid, as for ECU_BrakePressFront.";
CM_ SG_ 577 ECU_MotorTemp "Motor temperature, whole degC, from the inverter's INV_MotorRawTemp (its motor temperature input). Offset -40: raw 0 = -40 degC, clamped to -40..214. 0xFF (215) = invalid: the ECU has not heard the inverter, has lost it (comms timeout), or the inverter reports its 1381 sensor-fault value.";
CM_ SG_ 577 ECU_InverterTemp "Inverter temperature: the hottest of its three IGBT module temperatures (INV_ModuleA/B/CTemp), whole degC, offset -40, clamped to -40..214. 0xFF (215) = invalid: the ECU has not heard the inverter, or has lost it.";
CM_ BO_ 578 "MUR ADDITION (PROVISIONAL): the driver-interface state the ECU owns, for the screen: drive mode, the torque setting, traction control and fan requests, the startup stage and the APPS/brake plausibility (ABPC) state, plus the inverter's DC bus voltage for the precharge bar. Transmit rate 10 Hz (the ECU's best-effort thread). The dashboard forwards it to Dash CAN byte-for-byte, so it must stay identical in mur_dashboard_can.dbc (scripts/validate.py FORWARDED); every signal is byte-aligned and 8 or 16 bits wide for the MFD28. The mode selects a torque limit and that limit is applied (see ECU_TorqueSet). TC and the fan request are still DISPLAY ONLY: there is no traction control, and PDU_Control is unchanged.";
CM_ SG_ 578 ECU_DCBusVolt "Inverter DC bus voltage (INV_DCBusVoltage), as the ECU last received it on Tractive CAN. 0xFFFF (6553.5) = invalid: the ECU has not heard the inverter yet, or has lost it (comms timeout).";
CM_ SG_ 578 ECU_DashMode "Driver-selected mode, 1-5 (see VAL_). Cycled 1-2-3-4-5-1 by the dash mode button (Dashboard_Inputs DASH_ButtonStates bit 7); boots in Endurance. The ABPC page is not a mode: see ECU_ABPCActive. Selects the torque limit: each preset its own, Custom the driver's (see ECU_TorqueSet, including the wait for the throttle to lift after a change).";
CM_ SG_ 578 ECU_StartStage "Where the driver is in the ready-to-drive sequence (see VAL_). 0 = not available: tractive system off, or the car in Init/Fault/Shutdown. 1 = wait: tractive system on, the inverter fault-clear and 5 s startup wait still running. 2 = press the brake: Standby, the wait over, brake below the ready threshold. 3 = press the start button: as 2 with the brake above it. 4 = ready to drive (ReadyToDrive or Driving).";
CM_ SG_ 578 ECU_TorqueSet "The driver torque limit IN FORCE, whole Nm, APPLIED by the ECU (2026-11-14): commanded torque is capped at the lowest of this, the ECU power map (ECU_PowerMapSet) and the ECU's 160 Nm ceiling, with the pedal scaled to that cap so full pedal reaches it. Each preset mode has its own limit set in firmware: Accel 140, Skidpad 80, AutoX 120, Endurance 120 Nm (team values, 2026-11-14). In Custom the torque-down/up buttons - the screen's CAN switches 1 and 2, or the physical dash buttons (DASH_ButtonStates bits 4 and 5) - step it by 5 Nm within 10-160 Nm, taking effect at once; they do nothing in the presets, and Custom keeps its value while another mode is selected. After a MODE CHANGE the old mode's limit stays in force until the driver is off the throttle (deadzone, pedal stream lost, or not ReadyToDrive/Driving), so this shows the new mode's limit only once it has taken over. 120 Nm at power-up (Endurance). RAM only. If the dash goes quiet the ECU keeps the last selection.";
CM_ SG_ 578 ECU_TCEnabled "1 = traction control switched on by the driver (screen CAN switch 3, toggles on each change). Boots 0. There is no traction control in the firmware yet: this is the setting only.";
CM_ SG_ 578 ECU_FanRequest "1 = the driver interface wants the cooling fans running: always 1 while ECU_TSActive, otherwise the dash fan button's toggle (DASH_ButtonStates bit 6; boots 0). NOT SENT TO THE PDM yet - PDU_Control still requests Fan2 in every state (switching Fan2 off would also stop the pump and HighCurrent, see docs/PDM-Docs.md). PDU_Status shows the fans' actual state.";
CM_ SG_ 578 ECU_ABPCActive "1 = the APPS/brake pedal plausibility check is cutting torque: the ECU's TempBlock latch (brake above the ready threshold with more than 25 % throttle, held until throttle drops below 5 %) while ReadyToDrive or Driving. The dashboard flashes the screen's ABPC page (Dashboard_Display DASH_DispState = 9) while this is 1.";
CM_ BO_ 1794 "MUR ADDITION (PROVISIONAL): 1 Hz dashboard node heartbeat, ID 0x700 + node id (Dashboard = 2). Uptime, CAN error counters, low 16 bits of latched fault mask. Signals node-prefixed for bus-wide uniqueness.";
CM_ SG_ 1794 HB_DASH_FaultBits "Low 16 bits of the dashboard's latched fault mask. Only bit 0 is used (firmware/apps/dashboard in mur-embedded); the real fault map is still TBD.
bit 0: Analog dead; Dashboard ADC failed to start; warning";

BA_DEF_ BO_ "GenMsgCycleTime" INT 0 100000;
BA_DEF_ BO_ "GenMsgSendType" ENUM "Cyclic","OnChange","Event";
BA_DEF_ "BusType" STRING ;
BA_DEF_DEF_ "GenMsgCycleTime" 0;
BA_DEF_DEF_ "GenMsgSendType" "Cyclic";
BA_DEF_DEF_ "BusType" "CAN";
BA_ "GenMsgCycleTime" BO_ 336 10;
BA_ "GenMsgCycleTime" BO_ 512 10;
BA_ "GenMsgCycleTime" BO_ 513 50;
BA_ "GenMsgCycleTime" BO_ 514 100;
BA_ "GenMsgCycleTime" BO_ 515 10;
BA_ "GenMsgCycleTime" BO_ 528 100;
BA_ "GenMsgCycleTime" BO_ 530 500;
BA_ "GenMsgCycleTime" BO_ 529 100;
BA_ "GenMsgCycleTime" BO_ 560 200;
BA_ "GenMsgCycleTime" BO_ 561 500;
BA_ "GenMsgCycleTime" BO_ 576 100;
BA_ "GenMsgCycleTime" BO_ 579 100;
BA_ "GenMsgCycleTime" BO_ 516 50;
BA_ "GenMsgCycleTime" BO_ 577 100;
BA_ "GenMsgCycleTime" BO_ 578 100;
BA_ "GenMsgCycleTime" BO_ 518 100;
BA_ "GenMsgCycleTime" BO_ 1794 1000;
BA_ "GenMsgSendType" BO_ 128 2;

VAL_ 128 FAULT_Node 1 "Pedalbox" 2 "Dashboard" 3 "Rear" 4 "TTCS" 5 "Charger" ;
VAL_ 578 ECU_DashMode 1 "Accel" 2 "Skidpad" 3 "AutoX" 4 "Endurance" 5 "Custom" ;
VAL_ 578 ECU_StartStage 0 "NotAvailable" 1 "Wait" 2 "PressBrake" 3 "PressStart" 4 "ReadyToDrive" ;

CM_ BO_ 1760 "MUR ADDITION (PROVISIONAL, bench/demo): parameter-storage request endpoint for node 0, ID 0x6E0 + node. Classic-CAN ISO-TP: this frame is one 8-byte fragment (ISO-TP PCI byte + 7 data bytes), reassembled by the parameter service; telemetry must not treat the bytes as signals. Reserved block 0x6E0-0x6E7 requests, 0x6E8-0x6EF responses; canboot uses 0x7E0/0x7E8. ISO-TP flow control for a request arrives on 0x6E8 + node. Wire format, catalog and validation: generated/params/mur_params.h and mur_msgs.params. No parameter signal is finalized and no proto exists.";
CM_ BO_ 1768 "MUR ADDITION (PROVISIONAL, bench/demo): parameter-storage response endpoint for node 0, ID 0x6E8 + node. ISO-TP fragment of the shared 16-byte header plus at most 4096 payload bytes; see PARAM_Request and generated/params/mur_params.h. Never decoded as a signal.";
BA_ "GenMsgSendType" BO_ 1760 2;
BA_ "GenMsgSendType" BO_ 1768 2;
